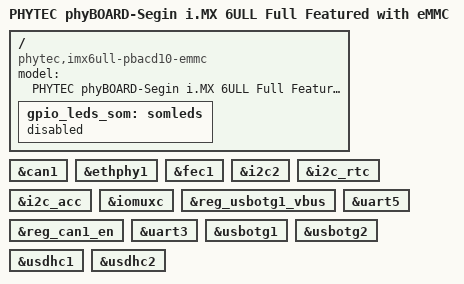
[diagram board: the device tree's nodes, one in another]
// SPDX-License-Identifier: (GPL-2.0+ OR MIT)
/*
 * Copyright (C) 2018 PHYTEC Messtechnik GmbH
 * Author: Stefan Riedmueller <s.riedmueller@phytec.de>
 */

/dts-v1/;
#include <dt-bindings/input/input.h>
#include "imx6ull.dtsi"
#include "imx6ull-phytec-phycore-som.dtsi"
#include "KSP-0689.dtsi"


/ {
	model = "PHYTEC phyBOARD-Segin i.MX 6ULL Full Featured with eMMC";
	compatible = "phytec,imx6ull-pbacd10-emmc", "phytec,imx6ull-pbacd10",
		     "phytec,imx6ull-pcl063","fsl,imx6ull";

	gpio_leds_som: somleds {
		status = "disabled";
	};
};

&can1 {
	status = "okay";
};

&ethphy1 {
	status = "okay";
};

&fec1 {
	status = "okay";
};

&i2c2 {
	status = "okay";
};

&i2c_rtc {
	status = "okay";
};

&i2c_acc {
	status = "okay";
};

&iomuxc {
	status = "okay";
};

&reg_usbotg1_vbus {
	status = "okay";
};

&reg_can1_en {
	status = "okay";
};

&uart5 {
	status = "okay";
};

&uart3 {
	status = "okay";
};

&usbotg1 {
	status = "okay";
};

&usbotg2 {
	status = "okay";
};

&usdhc1 {
	status = "okay";
};

&usdhc2 {
	status = "okay";
};

